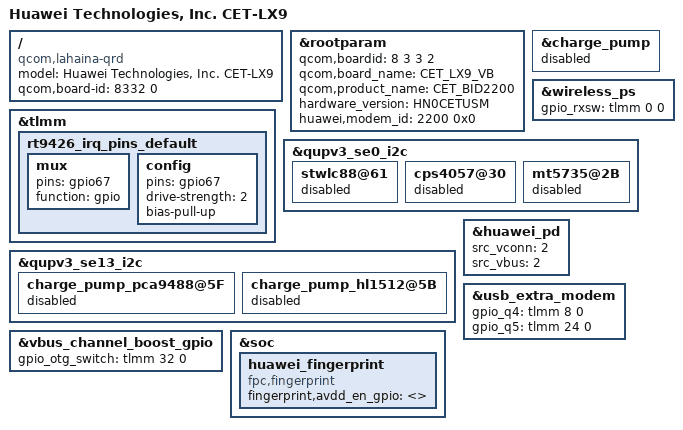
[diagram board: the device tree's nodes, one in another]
/dts-v1/;
/plugin/;

#include "../common/common.dtsi"
#include "huawei-nfc.dtsi"
#include "huawei_camera.dtsi"
#include "huawei_wifi.dtsi"
#include "huawei-bt.dtsi"
/ {
    /* bsp_replace_info @ model = "Huawei Technologies, Inc. %product_name%"; */
    model = "Huawei Technologies, Inc. CET-LX9";
    compatible = "qcom,lahaina-qrd", "qcom,lahaina", "qcom,qrd";
    /* bsp_replace_info @ qcom,board-id = <%boardid% 0>; */
    qcom,board-id = <8332 0>;
};

&rootparam {
    /* bsp_replace_info @ qcom,boardid = <%boardid_split%>; */
    /* auto_key_info @ name: boardid type: uint32 default: 0 */
    qcom,boardid = <8 3 3 2>;
    /* bsp_replace_info @ qcom,board_name = "%board_name%"; */
    qcom,board_name = "CET_LX9_VB";
    /* bsp_replace_info @ qcom,product_name = "%product_name%"; */
    qcom,product_name = "CET_BID2200";
    /* bsp_replace_info @ hardware_version = "%hardware_version%"; */
    hardware_version = "HN0CETUSM";
    /* bsp_replace_info @ huawei,modem_id = <%modem_id% 0x0>; */
    huawei,modem_id = <2200 0x0>;
};

&tlmm {
	rt9426_irq_pins_default {
		mux {
			pins = "gpio67";
			function = "gpio";
		};
		config {
			pins = "gpio67";
			drive-strength = <2>;
			bias-pull-up;
		};
	};
};

&charge_pump {
	status = "disabled";
};

&wireless_ps {
	gpio_rxsw = <&tlmm 0 0>;
};

&qupv3_se0_i2c {
	stwlc88@61 {
		status = "disabled";
	};

	cps4057@30 {
		status = "disabled";
	};

	mt5735@2B {
		status = "disabled";
	};
};

&qupv3_se13_i2c {
	charge_pump_pca9488@5F {
		status = "disabled";
	};

	charge_pump_hl1512@5B {
		status = "disabled";
	};
};

&huawei_pd {
	src_vconn = <2>; /* 5v-boost */
	src_vbus = <2>; /* 5v-boost */
};

&usb_extra_modem {
	gpio_q4 = <&tlmm 8 0>; /* GPIO_8 */
	gpio_q5 = <&tlmm 24 0>; /* GPIO_24 */
	status = "ok";
};

&vbus_channel_boost_gpio {
	gpio_otg_switch = <&tlmm 32 0>; /* GPIO_032 */
	status = "ok";
};

&soc {
	huawei_fingerprint {
		compatible = "fpc,fingerprint";
		fingerprint,avdd_en_gpio = <>;

		status = "ok";
	};
};
